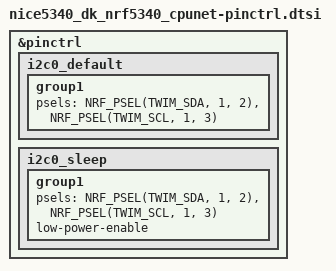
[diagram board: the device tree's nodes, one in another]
/*
 * Copyright (c) 2022 Nordic Semiconductor
 * SPDX-License-Identifier: Apache-2.0
 */

&pinctrl {
	i2c0_default: i2c0_default {
		group1 {
			psels = <NRF_PSEL(TWIM_SDA, 1, 2)>,
				<NRF_PSEL(TWIM_SCL, 1, 3)>;
		};
	};

	i2c0_sleep: i2c0_sleep {
		group1 {
			psels = <NRF_PSEL(TWIM_SDA, 1, 2)>,
				<NRF_PSEL(TWIM_SCL, 1, 3)>;
			low-power-enable;
		};
	};
};
